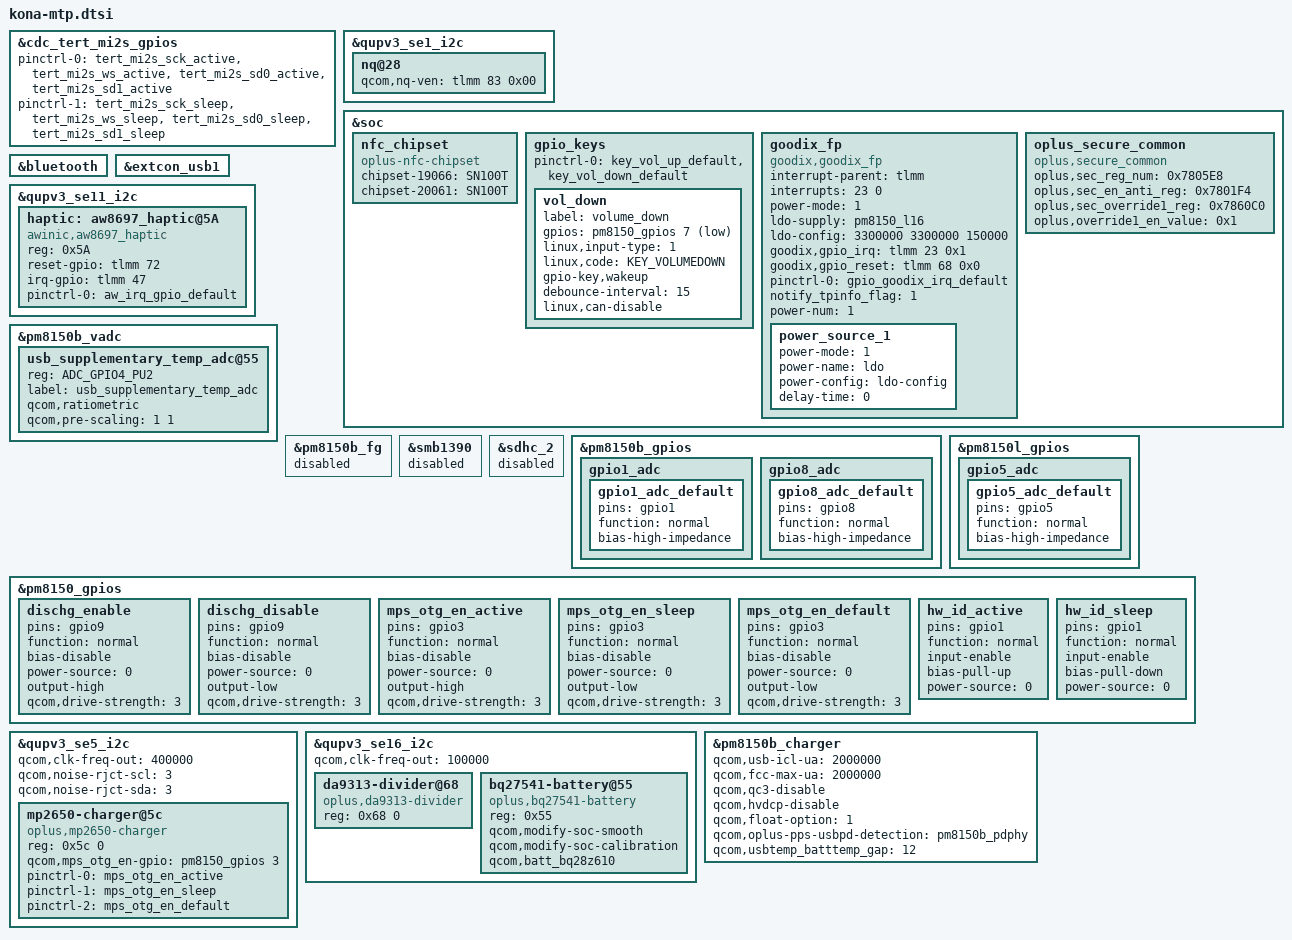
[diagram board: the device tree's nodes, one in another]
#include "kona-audio-overlay.dtsi"
#include "kona-pmic-overlay.dtsi"
#include "kona-sde-display.dtsi"

&cdc_tert_mi2s_gpios {
	pinctrl-0 = <&tert_mi2s_sck_active &tert_mi2s_ws_active
				&tert_mi2s_sd0_active &tert_mi2s_sd1_active>;
	pinctrl-1 = <&tert_mi2s_sck_sleep &tert_mi2s_ws_sleep
				&tert_mi2s_sd0_sleep &tert_mi2s_sd1_sleep>;
};

&qupv3_se1_i2c {
	/delete-property/ qcom,clk-freq-out;

	nq@28 {
		qcom,nq-ven = <&tlmm 83 0x00>;
	};
};

&soc {
	nfc_chipset {
		compatible = "oplus-nfc-chipset";
		chipset-19066 = "SN100T";
		chipset-20061 = "SN100T";
	};

	gpio_keys {
		pinctrl-0 = <&key_vol_up_default &key_vol_down_default>;

		vol_down {
			label = "volume_down";
			gpios = <&pm8150_gpios  7 GPIO_ACTIVE_LOW>;
			linux,input-type = <1>;
			linux,code = <KEY_VOLUMEDOWN>;
			gpio-key,wakeup;
			debounce-interval = <15>;
			linux,can-disable;
		};
	};

	goodix_fp {
		status = "ok";
		compatible = "goodix,goodix_fp";
		interrupt-parent = <&tlmm>;
		interrupts = <23 0>;
		power-mode = <1> ; /*please refer to the struct fp_power_mode_t in oplus_fp_commmon.n ,0: power mode not set, 1: ldo power, 2: gpio power, 3: auto power */
		ldo-supply = <&pm8150_l16>;
		ldo-config = <3300000 3300000 150000>;
		goodix,gpio_irq = <&tlmm 23 0x1>;
		goodix,gpio_reset = <&tlmm 68 0x0>;
		pinctrl-names = "default";
		pinctrl-0 = <&gpio_goodix_irq_default>;
		notify_tpinfo_flag = <1>;
		power-num = <1>;
		power_source_1 {
			power-mode = <1>;
			power-name = "ldo";
			power-config = "ldo-config";
			delay-time = <0>;
		};
	};

	oplus_secure_common {
		compatible = "oplus,secure_common";
		oplus,sec_reg_num = <0x7805E8>;
		oplus,sec_en_anti_reg = <0x7801F4>;
		oplus,sec_override1_reg = <0x7860C0>;
		oplus,override1_en_value = <0x1>;
	};
};

&bluetooth {
	/delete-property/ qca,bt-vdd-asd-supply;
	/delete-property/ qca,bt-vdd-asd-voltage-level;
};

&extcon_usb1 {
	/delete-property/ vbus-gpio;
	/delete-property/ vbus-out-gpio;
	/delete-property/ pinctrl-names;
	/delete-property/ pinctrl-0;
};

&qupv3_se11_i2c  {
	status = "ok";
	haptic: aw8697_haptic@5A {
		compatible = "awinic,aw8697_haptic";
		reg = <0x5A>;
		reset-gpio = <&tlmm 72 0>;
		irq-gpio = <&tlmm 47 0>;
		status = "ok";

		pinctrl-names = "default";
		pinctrl-0 = <&aw_irq_gpio_default>;
	};
};

&pm8150b_vadc {
	usb_supplementary_temp_adc@55 {
		reg = <ADC_GPIO4_PU2>;
		label = "usb_supplementary_temp_adc";
		qcom,ratiometric;
		qcom,pre-scaling = <1 1>;
	};
};

&pm8150b_fg {
	status = "disabled";
};

&smb1390 {
	status = "disabled";
};

&sdhc_2 {
	status = "disabled";
};

&pm8150b_gpios {
	gpio1_adc {
		gpio1_adc_default: gpio1_adc_default {
		pins = "gpio1"; /* GPIO 1 */
		function = "normal"; /* normal */
		bias-high-impedance; /* DISABLE GPIO1 for ADC*/
		};
	};

	gpio8_adc {
		gpio8_adc_default: gpio8_adc_default {
		pins = "gpio8"; /* GPIO 8 */
		function = "normal"; /* normal */
		bias-high-impedance; /* DISABLE GPIO8 for ADC*/
		};
	};

};

&pm8150l_gpios {
	gpio5_adc {
		gpio5_adc_default: gpio5_adc_default {
			pins = "gpio5"; /* GPIO 5 */
			function = "normal"; /* normal */
			bias-high-impedance; /* DISABLE GPIO5 for ADC*/
		};
	};
};

&pm8150_gpios {
	dischg_enable: dischg_enable {
		pins = "gpio9"; /* GPIO 9 */
		function = "normal"; /* normal */
		bias-disable; //No Pull
		power-source = <0>;//VIN0 3.3
		output-high; //digital output, no invert
		qcom,drive-strength = <3>; //LOW strength
		//drive-push-pull;//CMOS
	};

	dischg_disable: dischg_disable {
		pins = "gpio9"; /* GPIO 9 */
		function = "normal"; /* normal */
		bias-disable; //No Pull
		power-source = <0>;//VIN0 3.3
		output-low; //digital output, no invert
		qcom,drive-strength = <3>; //LOW strength
		//drive-push-pull;//CMOS
	};

	mps_otg_en_active: mps_otg_en_active {
		pins = "gpio3"; /* GPIO 3 */
		function = "normal"; /* normal */
		bias-disable; //No Pull
		power-source = <0>;//VIN1 1.8
		output-high; //digital output, no invert
		qcom,drive-strength = <3>; //LOW strength
		//drive-push-pull;//CMOS
	};
	mps_otg_en_sleep: mps_otg_en_sleep {
		pins = "gpio3"; /* GPIO 3 */
		function = "normal"; /* normal */
		bias-disable; //No Pull
		power-source = <0>;//VIN1 1.8
		output-low; //digital output, no invert
		qcom,drive-strength = <3>; //LOW strength
		//drive-push-pull;//CMOS
	};
	mps_otg_en_default: mps_otg_en_default {
		pins = "gpio3"; /* GPIO 3 */
		function = "normal"; /* normal */
		bias-disable; //No Pull
		power-source = <0>;//VIN1 1.8
		output-low; //digital output, no invert
		qcom,drive-strength = <3>; //LOW strength
		//drive-push-pull;//CMOS
	};

	hw_id_active: hw_id_active {
		pins = "gpio1"; /* GPIO 1 */
		function = "normal"; /* normal */
		input-enable;
		bias-pull-up;
		power-source = <0>;
	};

	hw_id_sleep: hw_id_sleep {
		pins = "gpio1"; /* GPIO 1 */
		function = "normal"; /* normal */
		input-enable;
		bias-pull-down;
		power-source = <0>;	/* 1.8V input supply */
	};
};

&qupv3_se5_i2c {
	status = "okay";
	qcom,clk-freq-out = <400000>;
	qcom,noise-rjct-scl = <3>;
	qcom,noise-rjct-sda = <3>;

	mp2650-charger@5c {
		status = "okay";
		compatible = "oplus,mp2650-charger";
		reg = <0x5c 0>;

		qcom,mps_otg_en-gpio = <&pm8150_gpios 3 0x00>;
		pinctrl-names = "mps_otg_en_active", "mps_otg_en_sleep", "mps_otg_en_default";
		pinctrl-0 = <&mps_otg_en_active>;
		pinctrl-1 = <&mps_otg_en_sleep>;
		pinctrl-2 = <&mps_otg_en_default>;

	};
};

&qupv3_se16_i2c {
	status = "okay";
	qcom,clk-freq-out = <100000>;

	da9313-divider@68 {
		status = "okay";
		compatible = "oplus,da9313-divider";
		reg = <0x68 0>;
	};

	bq27541-battery@55 {
		status = "okay";
		compatible = "oplus,bq27541-battery";
		reg = <0x55>;
		qcom,modify-soc-smooth;
		qcom,modify-soc-calibration;
		qcom,batt_bq28z610;
	};
};

&pm8150b_charger {
	//for smb5:
	qcom,usb-icl-ua = <2000000>;
	qcom,fcc-max-ua = <2000000>;
	qcom,qc3-disable;
	qcom,hvdcp-disable;
	qcom,float-option = <1>;
	qcom,oplus-pps-usbpd-detection = <&pm8150b_pdphy>;
	qcom,usbtemp_batttemp_gap = <12>;
};
